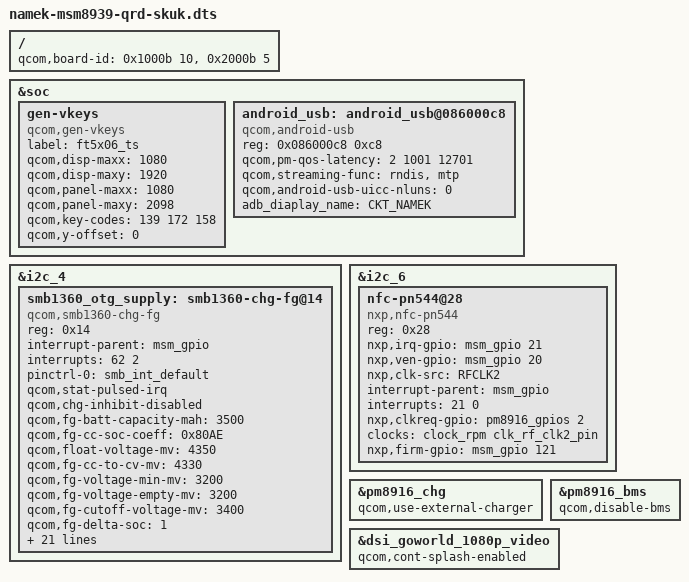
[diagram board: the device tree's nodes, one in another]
/* Copyright (c) 2014, The Linux Foundation. All rights reserved.
 *
 * This program is free software; you can redistribute it and/or modify
 * it under the terms of the GNU General Public License version 2 and
 * only version 2 as published by the Free Software Foundation.
 *
 * This program is distributed in the hope that it will be useful,
 * but WITHOUT ANY WARRANTY; without even the implied warranty of
 * MERCHANTABILITY or FITNESS FOR A PARTICULAR PURPOSE.  See the
 * GNU General Public License for more details.
 */

/dts-v1/;

#include "namek-msm8939.dtsi"
#include "./namek-msm8939-qrd-skuk/namek-msm8939-qrd-skuk.dtsi"
#include "./namek-msm8939-qrd-skuk/namek-dsi-panel-goworld-1080p-video.dtsi"
#include "./namek-msm8939-qrd-skuk/namek-msm8939-camera-sensor-qrd.dtsi"

/ {
	qcom,board-id = <0x1000b 10>, <0x2000b 5>;
};

&soc{
	gen-vkeys {
		compatible = "qcom,gen-vkeys";
		label = "ft5x06_ts";
		qcom,disp-maxx = <1080>;
		qcom,disp-maxy = <1920>;
		qcom,panel-maxx = <1080>;
		qcom,panel-maxy = <2098>;
		qcom,key-codes = <139 172 158>;
		qcom,y-offset = <0>;
	};

	android_usb: android_usb@086000c8 {
		compatible = "qcom,android-usb";
		reg = <0x086000c8 0xc8>;
		qcom,pm-qos-latency = <2 1001 12701>;
		qcom,streaming-func = "rndis","mtp";
		qcom,android-usb-uicc-nluns = /bits/ 8 <0>;
		adb_diaplay_name = "CKT_NAMEK";
	};
};

&i2c_4 {
	smb1360_otg_supply: smb1360-chg-fg@14 {
		compatible = "qcom,smb1360-chg-fg";
		reg = <0x14>;
		interrupt-parent = <&msm_gpio>;
		interrupts = <62 2>;
		pinctrl-names = "default";
		pinctrl-0 = <&smb_int_default>;
		qcom,stat-pulsed-irq;
		qcom,chg-inhibit-disabled;
		/*battery capacity*/
		qcom,fg-batt-capacity-mah = <3500>;
		qcom,fg-cc-soc-coeff = <0x80AE>;
		qcom,float-voltage-mv = <4350>;
		qcom,fg-cc-to-cv-mv = <4330>;
		qcom,fg-voltage-min-mv = <3200>;
		qcom,fg-voltage-empty-mv = <3200>;
		qcom,fg-cutoff-voltage-mv = <3400>;
		//qcom,fg-auto-recharge-soc = <99>;
		qcom,fg-delta-soc = <1>;
		qcom,thermistor-c1-coeff = <0x86C2>;
		qcom,iterm-ma = <200>;
		qcom,recharge-thresh-mv = <100>;
		qcom,charging-timeout = <1536>;
		qcom,otg-batt-curr-limit = <1500>;
		qcom,thermal-mitigation = <1500 700 600 0>;
		qcom,empty-soc-disabled;
		regulator-name = "smb1360_otg_vreg";
		qcom,fg-reset-at-pon;
		qcom,rsense-10mhom;

		qcom,batt-id-disabled;
		/*battery-profile selection properties */
		qcom,batt-profile-select;
		qcom,smb1360-vadc = <&pm8916_vadc>;
		qcom,batt-id-vref-uv = <1800000>;
		qcom,batt-id-rpullup-kohm = <100>;
		qcom,profile-a-rid-kohm = <33>;
		qcom,profile-b-rid-kohm = <91>;
		qcom,config-hard-thresholds;
		qcom,hot-bat-decidegc = <590>;
		qcom,cold-bat-decidegc = <(-200)>;
		qcom,hot-bat-mv = <4100>;
	};
};

//add by qidong
&i2c_6 {
    nfc-pn544@28 {
			compatible = "nxp,nfc-pn544";
			reg = <0x28>;
			nxp,irq-gpio = <&msm_gpio 21 0x00>;
			nxp,ven-gpio = <&msm_gpio 20 0x00>;
			nxp,clk-src = "RFCLK2";
			//nxp,clk-en-gpio = <&msm_gpio 0 0x00>;
			interrupt-parent = <&msm_gpio>;
			interrupts = <21 0>;
			interrupt-names = "nfc_irq";
			//pinctrl-names = "nfc_active","nfc_suspend";
			//pinctrl-0 = <&nfc_int_active &nfc_disable_active>;
			//pinctrl-1 = <&nfc_int_suspend &nfc_disable_suspend>;
			nxp,clkreq-gpio = <&pm8916_gpios 2 0>;
			clocks = <&clock_rpm clk_rf_clk2_pin>;
			clock-names = "ref_clk2";
			nxp,firm-gpio = <&msm_gpio 121 0x00>;
		};
};

&pm8916_chg {
	status = "ok";
	qcom,use-external-charger;
};

&pm8916_bms {
	status = "ok";
	qcom,disable-bms;
};

&dsi_goworld_1080p_video {
	qcom,cont-splash-enabled;
};
